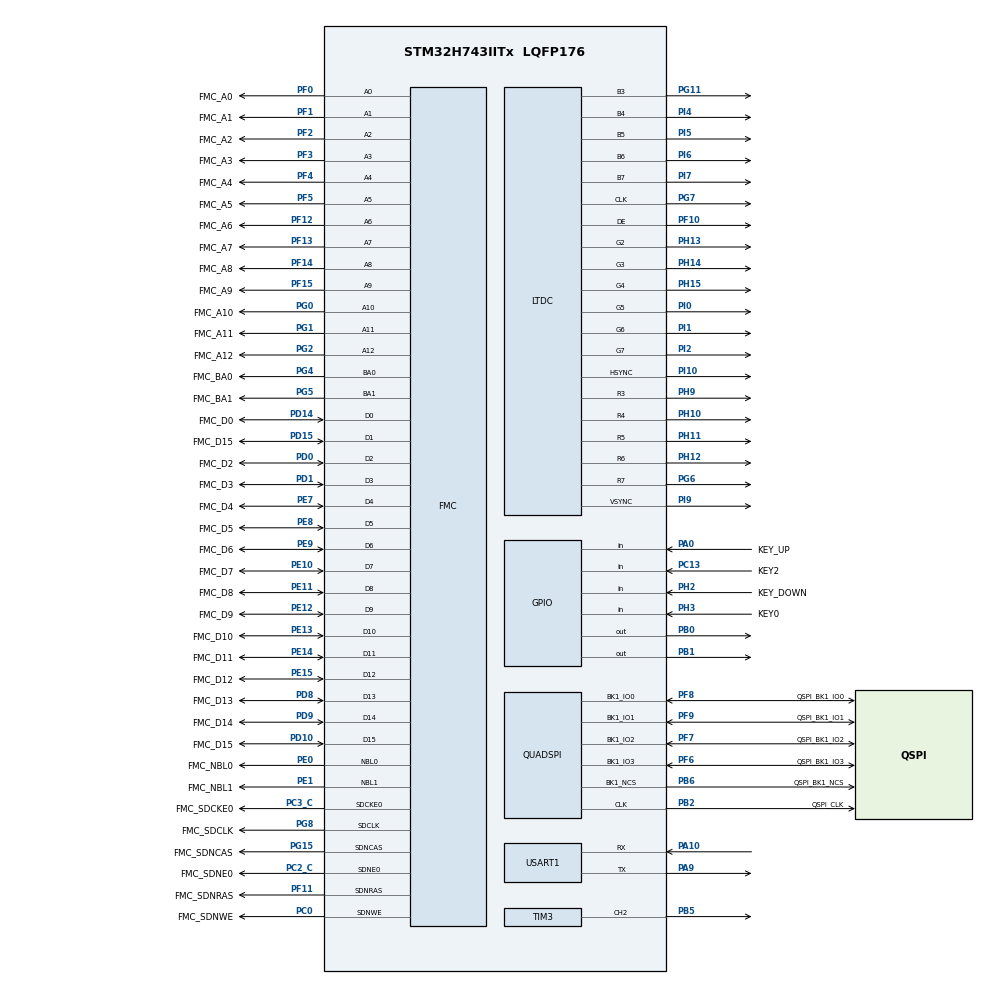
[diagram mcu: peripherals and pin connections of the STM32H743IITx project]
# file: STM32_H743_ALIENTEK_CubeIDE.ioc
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CORTEX_M7.AccessPermission_Spec=MPU_REGION_FULL_ACCESS
CORTEX_M7.BaseAddress_Spec=0xC0000000
CORTEX_M7.CPU_DCache=Enabled
CORTEX_M7.CPU_ICache=Enabled
CORTEX_M7.IsBufferable_Spec=MPU_ACCESS_NOT_BUFFERABLE
CORTEX_M7.IsCacheable_Spec=MPU_ACCESS_NOT_CACHEABLE
CORTEX_M7.IsShareable_Spec=MPU_ACCESS_NOT_SHAREABLE
CORTEX_M7.MPU_Control=MPU_HFNMI_PRIVDEF
CORTEX_M7.Size_Spec=MPU_REGION_SIZE_32MB
CORTEX_M7.SubRegionDisable_Spec=0x00
CORTEX_M7.TypeExtField_Spec=MPU_TEX_LEVEL1
CORTEX_M7.default_mode_Activation=1
DMA2D.ColorMode=DMA2D_OUTPUT_RGB565
DMA2D.InputColorModeForeground=DMA2D_INPUT_RGB565
DMA2D.Mode=DMA2D_M2M_PFC
FMC.CASLatency1=FMC_SDRAM_CAS_LATENCY_2
FMC.ColumnBitsNumber1=FMC_SDRAM_COLUMN_BITS_NUM_9
FMC.ExitSelfRefreshDelay1=14
FMC.LoadToActiveDelay1=2
FMC.RCDDelay1=3
FMC.RPDelay1=3
FMC.RPDelay2=3
FMC.ReadBurst1=FMC_SDRAM_RBURST_ENABLE
FMC.ReadBurst2=FMC_SDRAM_RBURST_ENABLE
FMC.RowCycleDelay1=12
FMC.RowCycleDelay2=12
FMC.SDClockPeriod1=FMC_SDRAM_CLOCK_PERIOD_2
FMC.SDClockPeriod2=FMC_SDRAM_CLOCK_PERIOD_2
FMC.SelfRefreshTime1=9
FMC.WriteRecoveryTime1=6
FREERTOS.Tasks01=defaultTask,24,1024,StartDefaultTask,Default,NULL,Dynamic,NULL,NULL
FREERTOS.configUSE_NEWLIB_REENTRANT=1
LTDC.ActiveW=800
LTDC.Alpha0_L0=255
LTDC.Alpha_L0=255
LTDC.DEPolarity=LTDC_DEPOLARITY_AL
LTDC.FBStartAdress_L0=0xC0000000
LTDC.HBP=88
LTDC.HFP=40
LTDC.HSync=48
LTDC.ImageHeight_L0=480
LTDC.ImageWidth_L0=1600
LTDC.Layers=0
LTDC.PCPolarity=LTDC_PCPOLARITY_IPC
LTDC.PixelFormat_L0=LTDC_PIXEL_FORMAT_RGB565
LTDC.VBP=32
LTDC.VFP=13
LTDC.VSync=3
LTDC.WindowX1_L0=800
LTDC.WindowY1_L0=480
Mcu.Family=STM32H7
Mcu.Name=STM32H743IITx
Mcu.Package=LQFP176
NVIC.DMA2D_IRQn=true\:5\:0\:false\:false\:true\:true\:true\:true\:true
NVIC.PriorityGroup=NVIC_PRIORITYGROUP_4
NVIC.TIM7_IRQn=true\:15\:0\:false\:false\:true\:false\:false\:true\:true
NVIC.TimeBase=TIM7_IRQn
NVIC.TimeBaseIP=TIM7
NVIC.USART1_IRQn=true\:5\:0\:false\:false\:true\:true\:true\:true\:true
PA0.GPIO_Label=KEY_UP
PA0.GPIO_PuPd=GPIO_PULLDOWN
PA0.Signal=GPIO_Input
PA10.Mode=Asynchronous
PA10.Signal=USART1_RX
PA9.Mode=Asynchronous
PA9.Signal=USART1_TX
PB0.GPIO_PuPd=GPIO_PULLUP
PB0.GPIO_Speed=GPIO_SPEED_FREQ_MEDIUM
PB0.PinState=GPIO_PIN_SET
PB0.Signal=GPIO_Output
PB1.GPIO_PuPd=GPIO_PULLUP
PB1.GPIO_Speed=GPIO_SPEED_FREQ_MEDIUM
PB1.PinState=GPIO_PIN_SET
PB1.Signal=GPIO_Output
PB2.GPIO_Label=QSPI_CLK
PB2.GPIO_Speed=GPIO_SPEED_FREQ_VERY_HIGH
PB2.Mode=Single Bank 1
PB2.Signal=QUADSPI_CLK
PB5.Signal=S_TIM3_CH2
PB6.GPIO_Label=QSPI_BK1_NCS
PB6.GPIO_Speed=GPIO_SPEED_FREQ_VERY_HIGH
PB6.Mode=Single Bank 1
PB6.Signal=QUADSPI_BK1_NCS
PC0.GPIO_Label=FMC_SDNWE
PC0.Signal=FMC_SDNWE
PC13.GPIO_Label=KEY2
PC13.GPIO_PuPd=GPIO_PULLUP
PC13.Signal=GPIO_Input
PC14-OSC32_IN\ (OSC32_IN).Mode=LSE-External-Oscillator
PC14-OSC32_IN\ (OSC32_IN).Signal=RCC_OSC32_IN
PC15-OSC32_OUT\ (OSC32_OUT).Mode=LSE-External-Oscillator
PC15-OSC32_OUT\ (OSC32_OUT).Signal=RCC_OSC32_OUT
PC2_C.GPIO_Label=FMC_SDNE0
PC2_C.Mode=SdramChipSelect1_1
PC2_C.Signal=FMC_SDNE0
PC3_C.GPIO_Label=FMC_SDCKE0
PC3_C.Mode=SdramChipSelect1_1
PC3_C.Signal=FMC_SDCKE0
PD0.GPIO_Label=FMC_D2
PD0.Signal=FMC_D2_DA2
PD1.GPIO_Label=FMC_D3
PD1.Signal=FMC_D3_DA3
PD10.GPIO_Label=FMC_D15
PD10.Signal=FMC_D15_DA15
PD14.GPIO_Label=FMC_D0
PD14.Signal=FMC_D0_DA0
PD15.GPIO_Label=FMC_D15
PD15.Signal=FMC_D1_DA1
PD8.GPIO_Label=FMC_D13
PD8.Signal=FMC_D13_DA13
PD9.GPIO_Label=FMC_D14
PD9.Signal=FMC_D14_DA14
PE0.GPIO_Label=FMC_NBL0
PE0.Signal=FMC_NBL0
PE1.GPIO_Label=FMC_NBL1
PE1.Signal=FMC_NBL1
PE10.GPIO_Label=FMC_D7
PE10.Signal=FMC_D7_DA7
PE11.GPIO_Label=FMC_D8
PE11.Signal=FMC_D8_DA8
PE12.GPIO_Label=FMC_D9
PE12.Signal=FMC_D9_DA9
PE13.GPIO_Label=FMC_D10
PE13.Signal=FMC_D10_DA10
PE14.GPIO_Label=FMC_D11
PE14.Signal=FMC_D11_DA11
PE15.GPIO_Label=FMC_D12
PE15.Signal=FMC_D12_DA12
PE7.GPIO_Label=FMC_D4
PE7.Signal=FMC_D4_DA4
PE8.GPIO_Label=FMC_D5
PE8.Signal=FMC_D5_DA5
PE9.GPIO_Label=FMC_D6
PE9.Signal=FMC_D6_DA6
PF0.GPIO_Label=FMC_A0
PF0.Signal=FMC_A0
PF1.GPIO_Label=FMC_A1
PF1.Signal=FMC_A1
PF10.Mode=RGB565
PF10.Signal=LTDC_DE
PF11.GPIO_Label=FMC_SDNRAS
PF11.Signal=FMC_SDNRAS
PF12.GPIO_Label=FMC_A6
PF12.Signal=FMC_A6
PF13.GPIO_Label=FMC_A7
PF13.Signal=FMC_A7
PF14.GPIO_Label=FMC_A8
PF14.Signal=FMC_A8
PF15.GPIO_Label=FMC_A9
PF15.Signal=FMC_A9
PF2.GPIO_Label=FMC_A2
PF2.Signal=FMC_A2
PF3.GPIO_Label=FMC_A3
PF3.Signal=FMC_A3
PF4.GPIO_Label=FMC_A4
PF4.Signal=FMC_A4
PF5.GPIO_Label=FMC_A5
PF5.Signal=FMC_A5
PF6.GPIO_Label=QSPI_BK1_IO3
PF6.GPIO_Speed=GPIO_SPEED_FREQ_VERY_HIGH
PF6.Mode=Single Bank 1
PF6.Signal=QUADSPI_BK1_IO3
PF7.GPIO_Label=QSPI_BK1_IO2
PF7.GPIO_Speed=GPIO_SPEED_FREQ_VERY_HIGH
PF7.Mode=Single Bank 1
PF7.Signal=QUADSPI_BK1_IO2
PF8.GPIO_Label=QSPI_BK1_IO0
PF8.GPIO_Speed=GPIO_SPEED_FREQ_VERY_HIGH
PF8.Mode=Single Bank 1
PF8.Signal=QUADSPI_BK1_IO0
PF9.GPIO_Label=QSPI_BK1_IO1
PF9.GPIO_Speed=GPIO_SPEED_FREQ_VERY_HIGH
PF9.Mode=Single Bank 1
PF9.Signal=QUADSPI_BK1_IO1
PG0.GPIO_Label=FMC_A10
PG0.Signal=FMC_A10
PG1.GPIO_Label=FMC_A11
PG1.Signal=FMC_A11
PG11.Mode=RGB565
PG11.Signal=LTDC_B3
PG15.GPIO_Label=FMC_SDNCAS
PG15.Signal=FMC_SDNCAS
PG2.GPIO_Label=FMC_A12
PG2.Signal=FMC_A12
PG4.GPIO_Label=FMC_BA0
PG4.Signal=FMC_A14_BA0
PG5.GPIO_Label=FMC_BA1
PG5.Signal=FMC_A15_BA1
PG6.Mode=RGB565
PG6.Signal=LTDC_R7
PG7.Mode=RGB565
PG7.Signal=LTDC_CLK
PG8.GPIO_Label=FMC_SDCLK
PG8.Signal=FMC_SDCLK
PH0-OSC_IN\ (PH0).Mode=HSE-External-Oscillator
PH0-OSC_IN\ (PH0).Signal=RCC_OSC_IN
PH1-OSC_OUT\ (PH1).Mode=HSE-External-Oscillator
PH1-OSC_OUT\ (PH1).Signal=RCC_OSC_OUT
PH10.Mode=RGB565
PH10.Signal=LTDC_R4
PH11.Mode=RGB565
PH11.Signal=LTDC_R5
PH12.Mode=RGB565
PH12.Signal=LTDC_R6
PH13.Mode=RGB565
PH13.Signal=LTDC_G2
PH14.Mode=RGB565
PH14.Signal=LTDC_G3
PH15.Mode=RGB565
PH15.Signal=LTDC_G4
PH2.GPIO_Label=KEY_DOWN
PH2.GPIO_PuPd=GPIO_PULLUP
PH2.Signal=GPIO_Input
PH3.GPIO_Label=KEY0
PH3.GPIO_PuPd=GPIO_PULLUP
PH3.Signal=GPIO_Input
PH9.Mode=RGB565
PH9.Signal=LTDC_R3
PI0.Mode=RGB565
PI0.Signal=LTDC_G5
PI1.Mode=RGB565
PI1.Signal=LTDC_G6
PI10.Mode=RGB565
PI10.Signal=LTDC_HSYNC
PI2.Mode=RGB565
PI2.Signal=LTDC_G7
PI4.Mode=RGB565
PI4.Signal=LTDC_B4
PI5.Mode=RGB565
PI5.Signal=LTDC_B5
PI6.Mode=RGB565
PI6.Signal=LTDC_B6
PI7.Mode=RGB565
PI7.Signal=LTDC_B7
PI9.Mode=RGB565
PI9.Signal=LTDC_VSYNC
ProjectManager.HeapSize=0x200
ProjectManager.StackSize=0x400
ProjectManager.TargetToolchain=STM32CubeIDE
QUADSPI.ClockPrescaler=1
QUADSPI.FifoThreshold=4
QUADSPI.FlashSize=24
RCC.ADCFreq_Value=96000000
RCC.APB1Freq_Value=100000000
RCC.APB2Freq_Value=100000000
RCC.APB3Freq_Value=100000000
RCC.APB4Freq_Value=100000000
RCC.CortexFreq_Value=400000000
RCC.D1PPRE=RCC_APB3_DIV2
RCC.D2PPRE1=RCC_APB1_DIV2
RCC.D2PPRE2=RCC_APB2_DIV2
RCC.D3PPRE=RCC_APB4_DIV2
RCC.DIVM1=5
RCC.DIVM2=25
RCC.DIVM3=25
RCC.DIVN1=160
RCC.DIVN2=192
RCC.DIVN3=216
RCC.DIVR3=8
RCC.HCLKFreq_Value=200000000
RCC.HPRE=RCC_HCLK_DIV2
RCC.PLLSourceVirtual=RCC_PLLSOURCE_HSE
RCC.SYSCLKFreq_VALUE=400000000
RCC.SYSCLKSource=RCC_SYSCLKSOURCE_PLLCLK
RCC.USBFreq_Value=400000000
SH.FMC_A0.0=FMC_A0,13b-sda1
SH.FMC_A1.0=FMC_A1,13b-sda1
SH.FMC_A10.0=FMC_A10,13b-sda1
SH.FMC_A11.0=FMC_A11,13b-sda1
SH.FMC_A12.0=FMC_A12,13b-sda1
SH.FMC_A14_BA0.0=FMC_BA0,FourSdramBanks1
SH.FMC_A15_BA1.0=FMC_BA1,FourSdramBanks1
SH.FMC_A2.0=FMC_A2,13b-sda1
SH.FMC_A3.0=FMC_A3,13b-sda1
SH.FMC_A4.0=FMC_A4,13b-sda1
SH.FMC_A5.0=FMC_A5,13b-sda1
SH.FMC_A6.0=FMC_A6,13b-sda1
SH.FMC_A7.0=FMC_A7,13b-sda1
SH.FMC_A8.0=FMC_A8,13b-sda1
SH.FMC_A9.0=FMC_A9,13b-sda1
SH.FMC_D0_DA0.0=FMC_D0,sd-16b-d1
SH.FMC_D10_DA10.0=FMC_D10,sd-16b-d1
SH.FMC_D11_DA11.0=FMC_D11,sd-16b-d1
SH.FMC_D12_DA12.0=FMC_D12,sd-16b-d1
SH.FMC_D13_DA13.0=FMC_D13,sd-16b-d1
SH.FMC_D14_DA14.0=FMC_D14,sd-16b-d1
SH.FMC_D15_DA15.0=FMC_D15,sd-16b-d1
SH.FMC_D1_DA1.0=FMC_D1,sd-16b-d1
SH.FMC_D2_DA2.0=FMC_D2,sd-16b-d1
SH.FMC_D3_DA3.0=FMC_D3,sd-16b-d1
SH.FMC_D4_DA4.0=FMC_D4,sd-16b-d1
SH.FMC_D5_DA5.0=FMC_D5,sd-16b-d1
SH.FMC_D6_DA6.0=FMC_D6,sd-16b-d1
SH.FMC_D7_DA7.0=FMC_D7,sd-16b-d1
SH.FMC_D8_DA8.0=FMC_D8,sd-16b-d1
SH.FMC_D9_DA9.0=FMC_D9,sd-16b-d1
SH.FMC_NBL0.0=FMC_NBL0,Sd2ByteEnable1
SH.FMC_NBL1.0=FMC_NBL1,Sd2ByteEnable1
SH.FMC_SDCLK.0=FMC_SDCLK,13b-sda1
SH.FMC_SDNCAS.0=FMC_SDNCAS,13b-sda1
SH.FMC_SDNRAS.0=FMC_SDNRAS,13b-sda1
SH.FMC_SDNWE.0=FMC_SDNWE,13b-sda1
SH.S_TIM3_CH2.0=TIM3_CH2,PWM Generation2 CH2
TIM3.AutoReloadPreload=TIM_AUTORELOAD_PRELOAD_ENABLE
TIM3.Channel-PWM\ Generation2\ CH2=TIM_CHANNEL_2
TIM3.Period=999
TIM3.Prescaler=199
TIM3.Pulse-PWM\ Generation2\ CH2=999
USART1.VirtualMode-Asynchronous=VM_ASYNC
VP_DMA2D_VS_DMA2D.Mode=DMA2D_Activate
VP_FREERTOS_VS_CMSIS_V2.Mode=CMSIS_V2
VP_MEMORYMAP_VS_MEMORYMAP.Mode=CurAppReg
VP_SYS_VS_tim7.Mode=TIM7
VP_TIM3_VS_ClockSourceINT.Mode=Internal
board=custom

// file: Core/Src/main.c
/* USER CODE BEGIN Header */
/**
  ******************************************************************************
  * @file           : main.c
  * @brief          : Main program body
  ******************************************************************************
  * @attention
  *
  * Copyright (c) 2026 STMicroelectronics.
  * All rights reserved.
  *
  * This software is licensed under terms that can be found in the LICENSE file
  * in the root directory of this software component.
  * If no LICENSE file comes with this software, it is provided AS-IS.
  *
  ******************************************************************************
  */
/* USER CODE END Header */
#include "main.h"
#include "FreeRTOS.h"
#include "cmsis_os2.h"
#include "dma2d.h"
#include "ltdc.h"
#include "quadspi.h"
#include "tim.h"
#include "usart.h"
#include "gpio.h"
#include "fmc.h"

/* USER CODE BEGIN Includes */
#include <stdio.h>
#include "qspi_flash.h"
/* USER CODE END Includes */

void SystemClock_Config(void);
static void MPU_Config(void);
void MX_FREERTOS_Init(void);

int main(void)
{

  /* MPU Configuration--------------------------------------------------------*/
  MPU_Config();

  /* Enable the CPU Cache */

  /* Enable I-Cache---------------------------------------------------------*/
  SCB_EnableICache();

  /* Enable D-Cache---------------------------------------------------------*/
  SCB_EnableDCache();

  /* MCU Configuration--------------------------------------------------------*/

  /* Reset of all peripherals, Initializes the Flash interface and the Systick. */
  HAL_Init();

  /* Configure the system clock */
  SystemClock_Config();

  /* Initialize all configured peripherals */
  MX_GPIO_Init();
  MX_USART1_UART_Init();
  MX_FMC_Init();
  MX_DMA2D_Init();
  MX_LTDC_Init();
  MX_QUADSPI_Init();
  MX_TIM3_Init();
  /* USER CODE BEGIN 2 */

  /* Enable IO compensation cell (required for FMC high-speed IOs) */
  HAL_EnableCompensationCell();

  /* Initialize QSPI flash (probe JEDEC, set 4-byte mode) */
  if (QSPI_Flash_Init() != HAL_OK)
  {
    printf("QSPI_Flash_Init failed\r\n");
  }

  /* QSPI write + mmap moved to animation task */

  /* JPEG decoder not used in Phase 6 (raw RGB565 on QSPI) */
  /* JPEG_Decoder_Init() removed */

  /* Enable BusFault, MemManage, UsageFault exceptions */
  SCB->SHCSR |= SCB_SHCSR_MEMFAULTENA_Msk | SCB_SHCSR_BUSFAULTENA_Msk | SCB_SHCSR_USGFAULTENA_Msk;

  /* USER CODE END 2 */

  /* Init scheduler */
  osKernelInitialize();  /* Call init function for freertos objects (in cmsis_os2.c) */
  MX_FREERTOS_Init();

  /* Start scheduler */
  osKernelStart();

  /* We should never get here as control is now taken by the scheduler */

  /* Infinite loop */
  while (1)
  {

  }
}

void SystemClock_Config(void)
{
  RCC_OscInitTypeDef RCC_OscInitStruct = {0};
  RCC_ClkInitTypeDef RCC_ClkInitStruct = {0};

  /** Supply configuration update enable
  */
  HAL_PWREx_ConfigSupply(PWR_LDO_SUPPLY);

  /** Configure the main internal regulator output voltage
  */
  __HAL_PWR_VOLTAGESCALING_CONFIG(PWR_REGULATOR_VOLTAGE_SCALE1);

  while(!__HAL_PWR_GET_FLAG(PWR_FLAG_VOSRDY)) {}

  /** Initializes the RCC Oscillators according to the specified parameters
  * in the RCC_OscInitTypeDef structure.
  */
  RCC_OscInitStruct.OscillatorType = RCC_OSCILLATORTYPE_HSE;
  RCC_OscInitStruct.HSEState = RCC_HSE_ON;
  RCC_OscInitStruct.PLL.PLLState = RCC_PLL_ON;
  RCC_OscInitStruct.PLL.PLLSource = RCC_PLLSOURCE_HSE;
  RCC_OscInitStruct.PLL.PLLM = 5;
  RCC_OscInitStruct.PLL.PLLN = 160;
  RCC_OscInitStruct.PLL.PLLP = 2;
  RCC_OscInitStruct.PLL.PLLQ = 2;
  RCC_OscInitStruct.PLL.PLLR = 2;
  RCC_OscInitStruct.PLL.PLLRGE = RCC_PLL1VCIRANGE_2;
  RCC_OscInitStruct.PLL.PLLVCOSEL = RCC_PLL1VCOWIDE;
  RCC_OscInitStruct.PLL.PLLFRACN = 0;
  if (HAL_RCC_OscConfig(&RCC_OscInitStruct) != HAL_OK)
  {
    Error_Handler();
  }

  /** Initializes the CPU, AHB and APB buses clocks
  */
  RCC_ClkInitStruct.ClockType = RCC_CLOCKTYPE_HCLK|RCC_CLOCKTYPE_SYSCLK
                              |RCC_CLOCKTYPE_PCLK1|RCC_CLOCKTYPE_PCLK2
                              |RCC_CLOCKTYPE_D3PCLK1|RCC_CLOCKTYPE_D1PCLK1;
  RCC_ClkInitStruct.SYSCLKSource = RCC_SYSCLKSOURCE_PLLCLK;
  RCC_ClkInitStruct.SYSCLKDivider = RCC_SYSCLK_DIV1;
  RCC_ClkInitStruct.AHBCLKDivider = RCC_HCLK_DIV2;
  RCC_ClkInitStruct.APB3CLKDivider = RCC_APB3_DIV2;
  RCC_ClkInitStruct.APB1CLKDivider = RCC_APB1_DIV2;
  RCC_ClkInitStruct.APB2CLKDivider = RCC_APB2_DIV2;
  RCC_ClkInitStruct.APB4CLKDivider = RCC_APB4_DIV2;

  if (HAL_RCC_ClockConfig(&RCC_ClkInitStruct, FLASH_LATENCY_2) != HAL_OK)
  {
    Error_Handler();
  }
}

/* USER CODE BEGIN 4 */

/* Redirect printf to USART1 */
int __io_putchar(int ch)
{
  HAL_UART_Transmit(&huart1, (uint8_t *)&ch, 1, HAL_MAX_DELAY);
  return ch;
}

/* USER CODE END 4 */

 /* MPU Configuration */

void MPU_Config(void)
{
  MPU_Region_InitTypeDef MPU_InitStruct = {0};

  /* Disables the MPU */
  HAL_MPU_Disable();

  /** Initializes and configures the Region and the memory to be protected
  */
  MPU_InitStruct.Enable = MPU_REGION_ENABLE;
  MPU_InitStruct.Number = MPU_REGION_NUMBER0;
  MPU_InitStruct.BaseAddress = 0xC0000000;
  MPU_InitStruct.Size = MPU_REGION_SIZE_32MB;
  MPU_InitStruct.SubRegionDisable = 0x00;
  MPU_InitStruct.TypeExtField = MPU_TEX_LEVEL1;
  MPU_InitStruct.AccessPermission = MPU_REGION_FULL_ACCESS;
  MPU_InitStruct.DisableExec = MPU_INSTRUCTION_ACCESS_DISABLE;
  MPU_InitStruct.IsShareable = MPU_ACCESS_NOT_SHAREABLE;
  MPU_InitStruct.IsCacheable = MPU_ACCESS_NOT_CACHEABLE;
  MPU_InitStruct.IsBufferable = MPU_ACCESS_NOT_BUFFERABLE;

  HAL_MPU_ConfigRegion(&MPU_InitStruct);
  /* Enables the MPU */
  HAL_MPU_Enable(MPU_HFNMI_PRIVDEF);

}

void HAL_TIM_PeriodElapsedCallback(TIM_HandleTypeDef *htim)
{
  if (htim->Instance == TIM7)
  {
    HAL_IncTick();
  }
}

void Error_Handler(void)
{
  __disable_irq();
  while (1)
  {
  }
}

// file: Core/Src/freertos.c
/* USER CODE BEGIN Header */
/**
  ******************************************************************************
  * File Name          : freertos.c
  * Description        : Code for freertos applications
  ******************************************************************************
  * @attention
  *
  * Copyright (c) 2026 STMicroelectronics.
  * All rights reserved.
  *
  * This software is licensed under terms that can be found in the LICENSE file
  * in the root directory of this software component.
  * If no LICENSE file comes with this software, it is provided AS-IS.
  *
  ******************************************************************************
  */
/* USER CODE END Header */

#include "FreeRTOS.h"
#include "task.h"
#include "main.h"
#include "FreeRTOS.h"
#include "cmsis_os2.h"

/* USER CODE BEGIN Includes */
#include <stdio.h>
#include "lcd.h"
#include "lvgl.h"
#include "lv_port_disp.h"
#include "lv_port_indev.h"
#include "animation.h"
#include "uart_protocol.h"
#include "lv_demo.h"
/* USER CODE END Includes */

/* USER CODE BEGIN Variables */
static osTimerId_t anim_timer_id;
static osTimerId_t lv_tick_timer_id;
osThreadId_t animTaskHandle;
const osThreadAttr_t animTask_attributes = {
  .name = "animation",
  .stack_size = 1024 * 8,
  .priority = (osPriority_t) osPriorityBelowNormal,
};
/* USER CODE END Variables */
/* Definitions for defaultTask */
osThreadId_t defaultTaskHandle;
const osThreadAttr_t defaultTask_attributes = {
  .name = "defaultTask",
  .stack_size = 1024 * 4,
  .priority = (osPriority_t) osPriorityNormal,
};

/* USER CODE BEGIN FunctionPrototypes */
void StartAnimationTask(void *argument);
void AnimTimerCallback(void *argument);
void LVTickCallback(void *argument);
/* USER CODE END FunctionPrototypes */

void StartDefaultTask(void *argument);

void MX_FREERTOS_Init(void); /* (MISRA C 2004 rule 8.1) */

void MX_FREERTOS_Init(void) {

  /* USER CODE BEGIN RTOS_TIMERS */
  /* start timers, add new ones, ... */
  anim_timer_id = osTimerNew(AnimTimerCallback, osTimerPeriodic, NULL, NULL);
  osTimerStart(anim_timer_id, 50U);  /* 50ms period for 20fps animation */
  /* 1ms LVGL tick timer */
  lv_tick_timer_id = osTimerNew(LVTickCallback, osTimerPeriodic, NULL, NULL);
  osTimerStart(lv_tick_timer_id, 1U);  /* 1ms lv_tick_inc(1) */
  /* USER CODE END RTOS_TIMERS */

  /* Create the thread(s) */
  /* creation of defaultTask */
  defaultTaskHandle = osThreadNew(StartDefaultTask, NULL, &defaultTask_attributes);

  /* USER CODE BEGIN RTOS_THREADS */
  /* add threads, ... */
  animTaskHandle = osThreadNew(StartAnimationTask, NULL, &animTask_attributes);
  /* USER CODE END RTOS_THREADS */

}

void StartDefaultTask(void *argument)
{
  /* USER CODE BEGIN StartDefaultTask */
  uint32_t sysclk, hclk, apb1, apb2;
  uint32_t sdram_base = 0xC0000000;
  uint32_t sdram_size = 0x02000000;
  uint32_t test_pattern, readback1, readback2, end_addr;
  int sdram_pass = 1;
  int led_tick = 0;

  /* Get system clock info */
  sysclk = (unsigned long)HAL_RCC_GetSysClockFreq() / 1000000;
  hclk   = (unsigned long)HAL_RCC_GetHCLKFreq() / 1000000;
  apb1   = (unsigned long)HAL_RCC_GetPCLK1Freq() / 1000000;
  apb2   = (unsigned long)HAL_RCC_GetPCLK2Freq() / 1000000;

  /* ---------- Serial output ---------- */
  printf("\r\n");
  printf("========================================\r\n");
  printf("  STM32H743 System Clock Info\r\n");
  printf("========================================\r\n");
  printf("  SYSCLK: %lu MHz\r\n", sysclk);
  printf("  HCLK:   %lu MHz\r\n", hclk);
  printf("  APB1:   %lu MHz\r\n", apb1);
  printf("  APB2:   %lu MHz\r\n", apb2);
  printf("========================================\r\n\n");

  printf("========================================\r\n");
  printf("  SDRAM Test (W9825G6KH)\r\n");
  printf("========================================\r\n");
  printf("  Base: 0x%08lX\r\n", (unsigned long)sdram_base);
  printf("  Size: %lu MB\r\n", (unsigned long)(sdram_size / 1024 / 1024));

  test_pattern = 0xAA55AA55;
  *((volatile uint32_t *)sdram_base) = test_pattern;
  readback1 = *((volatile uint32_t *)sdram_base);
  printf("  [0x%08lX] W:0x%08lX R:0x%08lX %s\r\n",
             (unsigned long)sdram_base, (unsigned long)test_pattern, (unsigned long)readback1,
             (readback1 == test_pattern) ? "OK" : "FAIL");
  if (readback1 != test_pattern) sdram_pass = 0;

  end_addr = sdram_base + sdram_size - 4;
  test_pattern = 0x55AA55AA;
  *((volatile uint32_t *)end_addr) = test_pattern;
  readback2 = *((volatile uint32_t *)end_addr);
  printf("  [0x%08lX] W:0x%08lX R:0x%08lX %s\r\n",
             (unsigned long)end_addr, (unsigned long)test_pattern, (unsigned long)readback2,
             (readback2 == test_pattern) ? "OK" : "FAIL");
  if (readback2 != test_pattern) sdram_pass = 0;

  printf("  Result: %s\r\n", sdram_pass ? "PASS" : "FAIL");
  printf("========================================\r\n\n");

  printf("Animation starting...\r\n");

  /* Turn on LCD backlight (LVGL will manage the display) */
  LCD_Init();

  /* Initialize LVGL and its ports */
  lv_init();
  lv_port_disp_init();
  lv_port_indev_init();

  /* Initialize UART1 protocol (ControlPCB communication) */
  uart_protocol_init();
  printf("UART1 protocol started (115200 baud)\r\n");

  /* Infinite loop - LED blink + LVGL task handling */
  for(;;)
  {
    /* LED blink: toggle every 500ms (100 ticks * 5ms) */
    led_tick++;
    if (led_tick >= 100)
    {
      HAL_GPIO_TogglePin(GPIOB, GPIO_PIN_0);
      led_tick = 0;
    }

    /* LVGL task handler: call frequently (5ms) when any LVGL page is active */
    if (lv_is_initialized() && current_page != PAGE_ANIMATION)
    {
      lv_task_handler();
    }

    /* Process UART1 protocol data (ring buffer -> frame parser) */
    uart_protocol_process();

    /* Diagnostic: print UART1 RX stats every 2 seconds */
    {
        static uint32_t last_irq = 0;
        static int diag_tick = 0;
        diag_tick++;
        if (diag_tick >= 400)  /* 400 * 5ms = 2s */
        {
            diag_tick = 0;
            uint32_t cur_irq = g_uart1_rx_irq_count;
            if (cur_irq != last_irq)
            {
                printf("[UART1] RX IRQ: %lu, overflow: %lu, rb: %u\r\n",
                       cur_irq, g_uart1_rb_overflow,
                       uart_rb_available(&g_uart_rb));
                last_irq = cur_irq;
            }
        }
    }

    /* Update Metrics pages with sensor data every 500ms */
    {
        static uint32_t sensor_tick = 0;
        static sensor_data_t sensor_data;
        sensor_tick++;
        if (sensor_tick >= 100)  /* 100 * 5ms = 500ms */
        {
            sensor_tick = 0;
            if (uart_protocol_has_data())
            {
                uart_protocol_get_data(&sensor_data);
                /* Update both Metrics pages so data is ready when user switches to them */
                lvgl_metrics1_update(&sensor_data);
                lvgl_metrics2_update(&sensor_data);
                /* Update animation page sensor numbers in real-time */
                UpdateAnimationSensorNumbers();
            }
        }
    }

    /* Process page switch requests from the AnimationTask.
     * All page switches (including LVGL calls like lv_scr_load, lv_refr_now)
     * must execute on the default task to avoid race conditions with lv_task_handler.
     */
    ProcessPageSwitch();

    osDelay(5);
  }
  /* USER CODE END StartDefaultTask */
}

/* USER CODE BEGIN Application */

/* LVGL 1ms tick callback - increments LVGL tick counter.
   Placed in USER CODE section so CubeMX won't overwrite it. */
void LVTickCallback(void *argument)
{
  (void)argument;
  lv_tick_inc(1);
}

/* USER CODE END Application */
